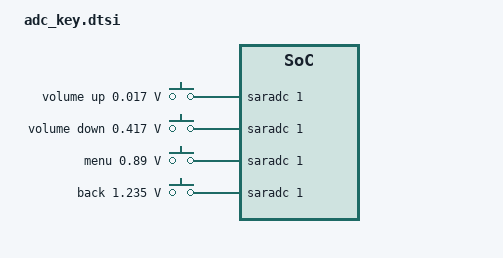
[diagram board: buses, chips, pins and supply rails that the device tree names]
/ {
	adc_keys: adc-keys {
		compatible = "adc-keys";
		io-channels = <&saradc 1>;
		io-channel-names = "buttons";
		keyup-threshold-microvolt = <1800000>;
		poll-interval = <100>;

		vol-up-key {
			label = "volume up";
			linux,code = <KEY_VOLUMEUP>;
			press-threshold-microvolt = <17000>;
		};

		vol-down-key {
			label = "volume down";
			linux,code = <KEY_VOLUMEDOWN>;
			press-threshold-microvolt = <417000>;
		};

		menu-key {
			label = "menu";
			linux,code = <KEY_MENU>;
			press-threshold-microvolt = <890000>;
		};

		back-key {
			label = "back";
			linux,code = <KEY_BACK>;
			press-threshold-microvolt = <1235000>;
		};
	};
};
